# psoc4200l register map
Vendor: Cypress Semiconductor; Series: PSoC4200L; File version: 1.0
CPU: CM0 r0p1, little endian, no MPU, no FPU, 2 interrupt priority bits
Registers are 32-bit, read-write, reset 0x0 unless marked. A register's access mark holds for its fields unless they carry their own. Offsets are from the block's base; [hi:lo] are bit positions; 'fields as' and 'values as' point back to an identical list; <NAME> marks a mode.

## CLK — External Crystal Oscillators and PLLs
Base 0x400C0000
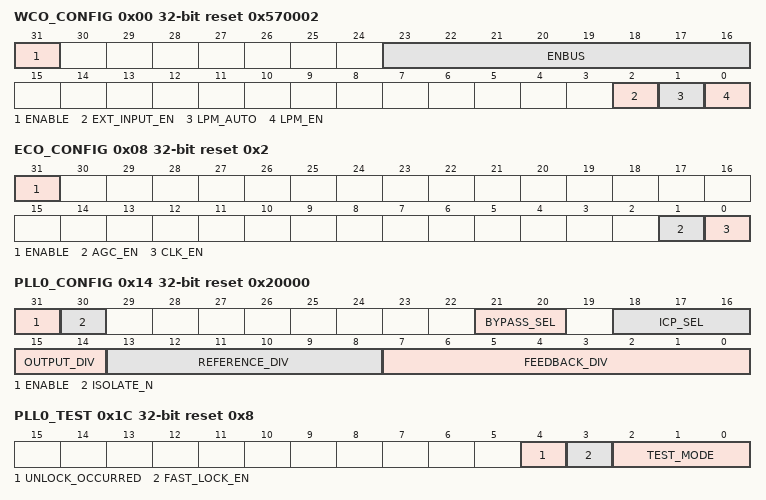
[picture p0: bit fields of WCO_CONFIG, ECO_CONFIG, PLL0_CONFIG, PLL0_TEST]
0x00 WCO_CONFIG reset 0x570002 — WCO Configuration Register
  [31] ENABLE — Master enable for WCO oscillator
  [23:16] ENBUS — Test Mode Control bits enbus[7] - N/A enbus[6] - 1=enable both primary Beta Multipliers enbus[5] - N/A enbus[4] - N/A enbus[3] - Load Resistor Control enbus[2] - Load Resistor Control enbus[1] - Load Resistor Control enbus[0] - Load Resistor Control
  [2] EXT_INPUT_EN — Disables the load resistor and allows external clock input for pad_xin
  [1] LPM_AUTO — Automatically control low power mode (only relevant when LPM_EN=0): 0: Do not enter low power mode (LPM) in DeepSleep 1: Enter low power mode (LPM) in DeepSleep
  [0] LPM_EN — Force block into Low Power Mode: 0: Do not force low power mode (LPM) on 1: Force low power mode (LPM) on
0x04 WCO_STATUS ro
  [0] OUT_BLNK_A — Indicates that output has transitioned. This bit is only for use in test mode and is not a reliable indicator.
0x08 ECO_CONFIG reset 0x2 — ECO Configuration Register
  [31] ENABLE — Master enable for ECO oscillator. Refer to CLK_EN for sequencing.
  [1] AGC_EN — Automatic Gain Control (AGC) enable. When set, the oscillation amplitude is controlled to the level selected by ECO_TRIM0.ATRIM. When low, the amplitude is not explicitly controlled and will grow until it saturates to the supply rail (1.8V nom). WARNING: use care when disabling AGC because driving a crystal beyond its rated limit can permanently damage the crystal.
  [0] CLK_EN — Clock Enable. When enabling the clock, first write ENABLE=1, wait at least 10us, and then write CLK_EN=1. When disabling, clearing both CLK_EN=0 and ENABLE=0 can be done in the same AHB write
0x0C ECO_STATUS ro reset 0x1
  [0] WATCHDOG_ERROR — This bit is set to 1 if the oscillator is stuck. The ECO clock is gated off during a watchdog error condition. Due to internal synchonization, the clock is stopped two cycles after an error condition is observed and ungated two cycles after the error condition is resolved.
0x14 PLL0_CONFIG reset 0x20000 — PLL #0 Configuration Register
  [31] ENABLE — Master enable for PLL power gate. Refer to ISOLATE_N field for required sequencing. 0: Block is powered off 1: Block is powered on
  [30] ISOLATE_N — Isolation control of PLL outputs. This also internally resets the PLL. De-assert >= 5us after ENABLE=1. Assertion can happen in same write as ENABLE=0. Do not change while PLL output is selected. 0: Isolate outputs; Precharge PLL control voltage if PLL0_TEST.FAST_LOCK_EN is set to 1. 1: Do not isolate outputs
  [21:20] BYPASS_SEL — Selects the source of the system PLL0 clock.
    0=AUTO (Automatic using lock indicator. When unlocked, automatically selects PLL reference input (bypass mode). When locked, automatically selects PLL output.); 1=AUTO1 (Same as AUTO); 2=PLL_REF (Select PLL reference input (bypass mode). Ignores lock indicator); 3=PLL_OUT (Select PLL output. Ignores lock indicator.)
  [18:16] ICP_SEL — Programmable charge pump current between 0uA and 7uA. Do not change while the PLL output is selected. For functional operation, the value must be set according to the PLL output frequency Fout (measured before the output divider): 0: 0uA (Hi-Z) Engineering use only 1: 1uA. Engineering use only 2: 2uA. Use when Fout <= 67MHz 3: 3uA. Use when Fout > 67MHz 4-7: 4uA-7uA. Engineering use only
  [15:14] OUTPUT_DIV — Control bits for Output divider. Do not change while PLL output is selected.
    0=PASS (Pass Through); 1=DIV2 (Divide by 2); 2=DIV4 (Divide by 4); 3=DIV8 (Divide by 8)
  [13:8] REFERENCE_DIV — Control bits for reference divider: Divide by 2=0001, ..., divide by 64=111111. Do not change while PLL output is selected.
  [7:0] FEEDBACK_DIV — Control bits for feedback divider: Valid divide is 8-256. Do not change while PLL output is selected.
0x18 PLL0_STATUS ro
  [0] LOCKED — PLL Lock Indicator
0x1C PLL0_TEST reset 0x8
  [4] UNLOCK_OCCURRED — This bit sets whenever the PLL Lock bit goes low, and stays set until cleared by firmware. This is a diagnostic bit used for char and validation.
  [3] FAST_LOCK_EN — Fast Lock Enable - Speeds up the lock time when set to 1. When ISOLATE_N is high, the PLL control voltage will be precharged to reduce time spent acquiring frequency lock.
  [2:0] TEST_MODE
    0=NORMAL (Normal Operation); 1=TEST_VC_LKG (Vcontrol Leakage Test Mode Measure frequency drift over time to indirectly measure leakage on Vcontrol); 2=TEST_CP_DN (Charge Pump Down Current Test Mode With ICPSEL>0, directly measure charge pump up current on Vcontrol With ICPSEL=0, directly measure leakage on Vcontrol With ICPSEL=0, FAST_LOCK_EN=0 and ISOLATE_N=0, directly measure discharge current on Vcontrol With ICPSEL=0, FAST_LOCK_EN=1 and ISOLATE_N=0, directly measure precharge current on Vcontrol); 3=TEST_CP_UP (Charge Pump Up Current Test Mode With ICPSEL>0, directly measure charge pump up current on Vcontrol With ICPSEL=0, directly measure leakage on Vcontrol With ICPSEL=0, FAST_LOCK_EN=0 and ISOLATE_N=0, directly measure discharge current on Vcontrol With ICPSEL=0, FAST_LOCK_EN=1 and ISOLATE_N=0, directly measure precharge current on Vcontrol); 4=USER_EXT_FL (User Mode with Extended Fast Lock Precharge); 5=TEST_CTR_PQ (Reference and Feedback Counter Test Mode); 6=TEST_LD_DLY (Lock Detector Delay Line Test Mode); 7=TEST_CTR_ALT (Lock Detector Wait and Extended Fast Lock Counter Test Mode With ICPSEL=0 and Reference Clock stopped directly measure precharge current on Vcontrol With ICPSEL=0 and Reference Clock running directly measure leakage on Vcontrol)
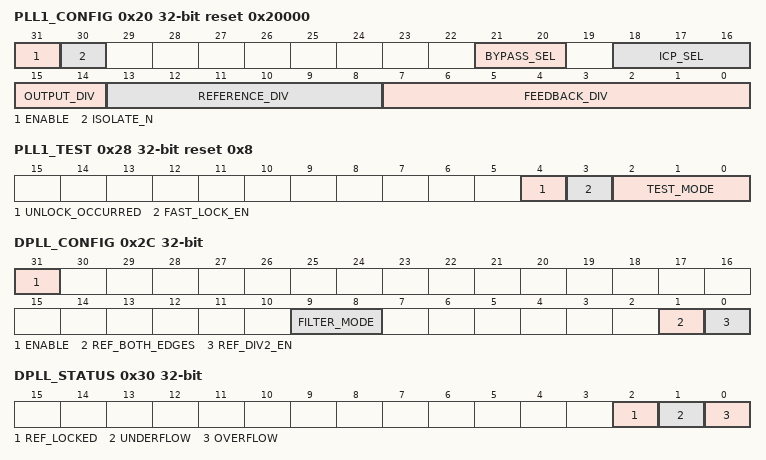
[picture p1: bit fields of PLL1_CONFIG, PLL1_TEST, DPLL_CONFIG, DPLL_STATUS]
0x20 PLL1_CONFIG reset 0x20000 — PLL #1 Configuration Register
  [31] ENABLE — Master enable for PLL power gate. Refer to ISOLATE_N field for required sequencing. 0: Block is powered off 1: Block is powered on
  [30] ISOLATE_N — Isolation control of PLL outputs. This also internally resets the PLL. De-assert >= 5us after ENABLE=1. Assertion can happen in same write as ENABLE=0. Do not change while PLL output is selected. 0: Isolate outputs; Precharge PLL control voltage if PLL0_TEST.FAST_LOCK_EN is set to 1. 1: Do not isolate outputs
  [21:20] BYPASS_SEL — Selects the source of the system PLL1 clock.
    values as PLL0_CONFIG.BYPASS_SEL
  [18:16] ICP_SEL — Programmable charge pump current between 0uA and 7uA. Do not change while the PLL output is selected. For functional operation, the value must be set according to the PLL output frequency Fout (measured before the output divider): 0: 0uA (Hi-Z) Engineering use only 1: 1uA. Engineering use only 2: 2uA. Use when Fout <= 67MHz 3: 3uA. Use when Fout > 67MHz 4-7: 4uA-7uA. Engineering use only
  [15:14] OUTPUT_DIV — Control bits for Output divider. Do not change while PLL output is selected.
    values as PLL0_CONFIG.OUTPUT_DIV
  [13:8] REFERENCE_DIV — Control bits for reference divider: Divide by 2=0001, ..., divide by 64=111111. Do not change while PLL output is selected.
  [7:0] FEEDBACK_DIV — Control bits for feedback divider: Valid divide is 8-256. Do not change while PLL output is selected.
0x24 PLL1_STATUS ro
  [0] LOCKED — PLL Lock Indicator
0x28 PLL1_TEST reset 0x8
  fields as PLL0_TEST
0x2C DPLL_CONFIG — DPLL Configuration Register
  [31] ENABLE — Master enable for DPLL. Setting ENABLE=1 will startup the tracking DPLL. No output clock will be generated until the frequency lock has been established. The status of the DPLL can be observed in the DPLL_STATUS register.
  [9:8] FILTER_MODE — Select the transfer function for the (IIR) feedback filter: 0: out[i] = in[i] 1: out[i] = in[i] + out[i-1] 2: out[i] = in[i] + 2*out[i-1] - out[i-2]
  [1] REF_BOTH_EDGES — Use both edges of the synchronized signal. Must be used when REF_DIV2_EN=1, can be used optionally when it is 0.
  [0] REF_DIV2_EN — Divide input reference by 2 before double synchronizing to input clock. Use this option when the pulse length of the input reference is not guaranteed to be at least 2x the cycle time of the selected input clock (for example when using trigger signals or other short-pulse-type signals).
0x30 DPLL_STATUS
  [2] REF_LOCKED ro — Indicates whether the DPLL has locked to the input reference. 0: Not locked. No output clock is generated. 1: Locked. Output clock is being generated.
  [1] UNDERFLOW — The accumulator has underflowed and wrapped around. The DPLL will continue to run and generated output clock, but with (severely) reduced accuracy. This bit is sticky and must be cleared by firmware. This condition should never happen under normal circumstances and is indicative of excessive input clock jitter or invalid parameter settings.
  [0] OVERFLOW — The accumulator has overflowed and wrapped around. The DPLL will continue to run and generated output clock, but with (severely) reduced accuracy. This bit is sticky and must be cleared by firmware. This condition should never happen under normal circumstances and is indicative of excessive input clock jitter or invalid parameter settings.
0x34 DPLL_L — DPLL L Parameter
  [7:0] L — Dithering input divider fact. The input divider divides by L or (L-1) depending on the accumulator/filter feedback.
0x38 DPLL_N — DPLL N Parameter
  [7:0] N — Accumulator contribution for each input clock cycle in the reference clock period. Used to calculate N*C, where C is the number of cycles in the reference clock period. This term is added to the accumulator on every output clock period.
0x3C DPLL_M — DPLL M Parameter
  [15:0] M — Accumulator contribution for each input clock cycle in the output clock period. Subtracted from CLK_DPLL_LM to calculate (L-1)*M when output clock period is L-1 cycles long. This term is subtracted from the accumulator on every output clock period.
0x40 DPLL_LM — DPLL L*M Parameter
  [23:0] LM — Accumulator contribution for each output clock period. This value must be equal to CLK_DPLL_L * CLK_DPLL_M.
0x44 DPLL_T — DPLL T Parameter
  [23:0] T — Quantizer value. The dithering divider divides by L-1 if filter output is <CLK_DPLL_T, and by L if filter output is >=CLK_DPLL_T.
0x48 DPLL_R — DPLL R Parameter
  [7:0] R — This is the magnitude of the random noise component added to the accumulator on every output clock cycle. Either +R or -R is added depending on the output of a 12-bit LFSR. The interpretation of this LFSR alternates back and forth (0=+R/1=-R and 0=-R/1=+R) to ensure that no DC noise component is added to the accumulator over time. The 12-bit pseudo-random LFSR has a generator polynomial (x^12+x^11+x^10+x^4+1). This polynomial has period 4095 (it does not produce the value 12'b0), which means that the total period of the pseudo-random sequence is 8190 output clock cycles.
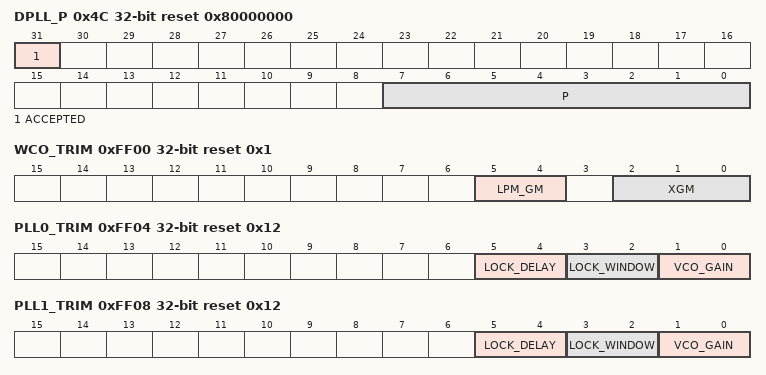
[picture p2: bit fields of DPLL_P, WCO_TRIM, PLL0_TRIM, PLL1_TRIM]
0x4C DPLL_P reset 0x80000000 — DPLL P Parameter
  [31] ACCEPTED — When a new P value is written set this bit to 1 to clear this bit. 0: The value for P in this register is being synchronized to the DPLL. Do not write to this register unless ENABLE=0 1: The value for P in this register has been accepted by the DPLL logic. Another value can be written. It takes 2-3 cycles of the DPLL input clock and 2-3 cycles of the system clock for synchronization to happen.
  [7:0] P — Pull component. This number is sign-extended and added on each output clock cycle to the accumulator.
0x50 OSCINTF_CTL — Oscillator Interface Control
  [0] PORT_SEL — Oscillator Interface Port Select 0: USB Selected 1: WCO Selected
0xFF00 WCO_TRIM reset 0x1
  [5:4] LPM_GM — GM setting for LPM (bandwidth = DC/ms)
  [2:0] XGM — Amplifier GM setting 0x0 - 3370 nA 0x1 - 2620 nA 0x2 - 2250 nA 0x3 - 1500 nA 0x4 - 1870 nA 0x5 - 1120 nA 0x6 - 750 nA 0x7 - 0 nA
0xFF04 PLL0_TRIM reset 0x12
  [5:4] LOCK_DELAY — Selects the number of PLL phase frequency detector cycles that the phase error must be in range before declaring lock. (PFD clock cycle = Clock Reference Period/REFERENCE_DIV)
    0=PFD_CLK_16 (16 PFD clock cycles); 1=PFD_CLK_32 (32 PFD clock cycles); 2=PFD_CLK_48 (48 PFD clock cycles); 3=PFD_CLK_64 (64 PFD clock cycles)
  [3:2] LOCK_WINDOW — Selects the allowed phase error before declaring the PLL Unlocked
    0=DELAY_25NS; 1=DELAY_50NS; 2=DELAY_75NS; 3=DELAY_100NS
  [1:0] VCO_GAIN — Programmable VCO frequency characteristic at high freq - set to <10>
0xFF08 PLL1_TRIM reset 0x12
  fields as PLL0_TRIM
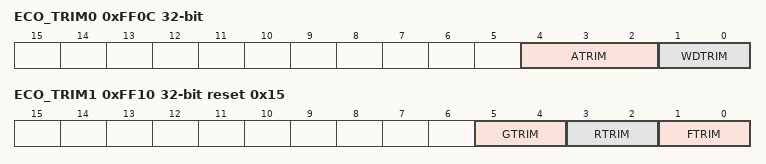
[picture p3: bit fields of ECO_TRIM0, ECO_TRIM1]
0xFF0C ECO_TRIM0
  [4:2] ATRIM — Amplitude trim to set the crystal drive level when ECO_CONFIG.AGC_EN=1. WARNING: use care when setting this field because driving a crystal beyond its rated limit can permanently damage the crystal. 0x0 - 0.3Vpp 0x1 - 0.4Vpp 0x2 - 0.5Vpp 0x3 - 0.6Vpp 0x4 - 0.7Vpp 0x5 - 0.8Vpp 0x6 - 0.9Vpp 0x7 - 1.0Vpp
  [1:0] WDTRIM — Watch Dog Trim - Delta voltage below stead state level 0x0 - 0.05V 0x1 - 0.1V 0x2 - 0.15V 0x3 - 0.2V
0xFF10 ECO_TRIM1 reset 0x15
  [5:4] GTRIM — Gain Trim - Startup time
  [3:2] RTRIM — Feedback resistor Trim
  [1:0] FTRIM — Filter Trim - 3rd harmonic oscillation
0xFF14 ECO_TRIM2 reset 0x20
  [5:0] ITRIM — Current Trim
